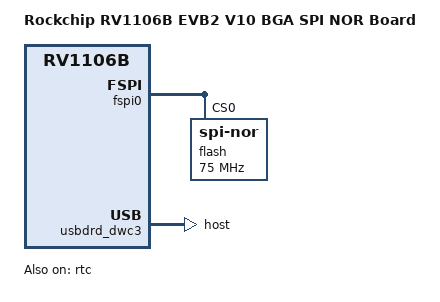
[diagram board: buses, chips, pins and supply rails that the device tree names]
// SPDX-License-Identifier: (GPL-2.0+ OR MIT)
/*
 * Copyright (c) 2026 Rockchip Electronics Co., Ltd.
 *
 */

/dts-v1/;

#include "rv1106b-evb2-v10-bga.dtsi"

/ {
	model = "Rockchip RV1106B EVB2 V10 BGA SPI NOR Board";
	compatible = "rockchip,rv1106b-evb2-v10-bga-spi-nor", "rockchip,rv1106b";
};

&fiq_debugger {
	rockchip,baudrate = <1500000>;
};

&gmac {
	status = "disabled";
};

&fspi0 {
	status = "okay";

	flash@0 {
		compatible = "jedec,spi-nor";
		reg = <0>;
		spi-max-frequency = <75000000>;
		spi-rx-bus-width = <4>;
		spi-tx-bus-width = <1>;
	};
};

&rockchip_suspend {
	status = "okay";

	rockchip,sleep-io-config = <
		/* pmic_sleep */
		(0
		| RKPM_IO_CFG_IOMUX_GPIO
		| RKPM_IO_CFG_GPIO_DIR_INPUT
		| RKPM_IO_CFG_PULL_DOWN
		| RKPM_IO_CFG_ID(0)
		)
		(0
		| RKPM_IO_CFG_IOMUX_GPIO
		| RKPM_IO_CFG_GPIO_DIR_INPUT
		| RKPM_IO_CFG_PULL_NONE
		| RKPM_IO_CFG_ID(1)
		)
		(0
		| RKPM_IO_CFG_IOMUX_GPIO
		| RKPM_IO_CFG_GPIO_DIR_INPUT
		| RKPM_IO_CFG_PULL_NONE
		| RKPM_IO_CFG_ID(2)
		)
		(0
		| RKPM_IO_CFG_IOMUX(1)
		| RKPM_IO_CFG_PULL_NONE
		| RKPM_IO_CFG_ID(3)
		)
		(0
		| RKPM_IO_CFG_IOMUX_GPIO
		| RKPM_IO_CFG_GPIO_DIR_INPUT
		| RKPM_IO_CFG_PULL_UP
		| RKPM_IO_CFG_ID(4)
		)
		(0
		| RKPM_IO_CFG_IOMUX_GPIO
		| RKPM_IO_CFG_GPIO_DIR_INPUT
		| RKPM_IO_CFG_PULL_DOWN
		| RKPM_IO_CFG_ID(5)
		)
		(0
		| RKPM_IO_CFG_IOMUX_GPIO
		| RKPM_IO_CFG_GPIO_DIR_INPUT
		| RKPM_IO_CFG_PULL_DOWN
		| RKPM_IO_CFG_ID(6)
		)
	>;
};

&rtc {
	rockchip,rtc-suspend-bypass;
	status = "okay";
};

&usbdrd_dwc3 {
	dr_mode = "host";
};
